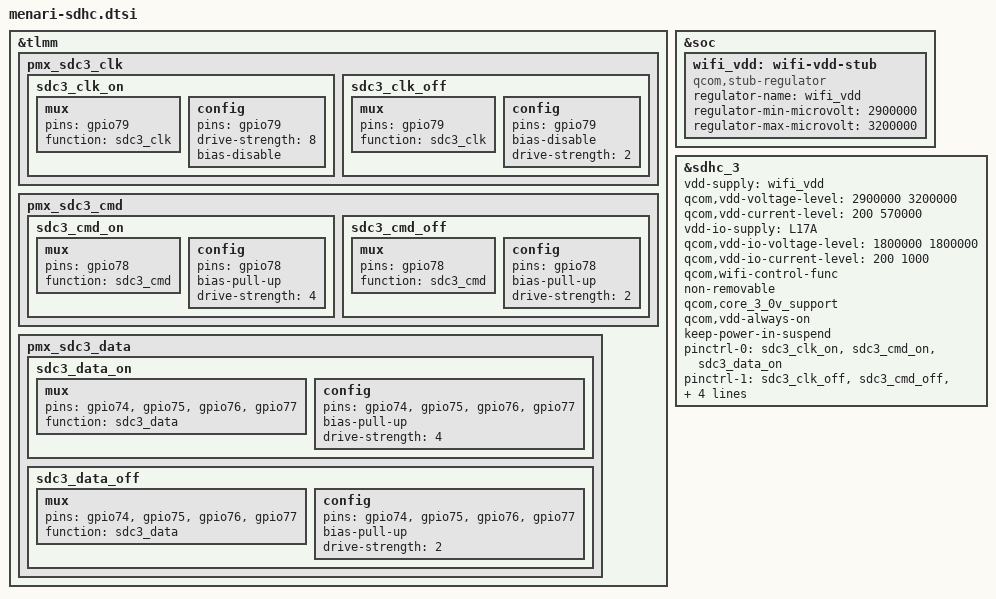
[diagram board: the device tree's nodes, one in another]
// SPDX-License-Identifier: GPL-2.0-only
// Google Agumon wlan SDIO device tree source

&tlmm {
	/* SDC3 Pin Ctrl */
	pmx_sdc3_clk {
		sdc3_clk_on: sdc3_clk_on {
			mux {
				pins = "gpio79";
				function = "sdc3_clk";
			};
			config {
				pins = "gpio79";
				drive-strength = <8>; /* 8 MA */
				bias-disable; /* NO pull */
			};
		};
		sdc3_clk_off: sdc3_clk_off {
			mux {
				pins = "gpio79";
				function = "sdc3_clk";
			};
			config {
				pins = "gpio79";
				bias-disable; /* NO pull */
				drive-strength = <2>; /* 2 MA */
			};
		};
	};
	pmx_sdc3_cmd {
		sdc3_cmd_on: sdc3_cmd_on {
			mux {
				pins = "gpio78";
				function = "sdc3_cmd";
			};
			config {
				pins = "gpio78";
				bias-pull-up; /* pull up */
				drive-strength = <4>; /* 4 MA */
			};
		};
		sdc3_cmd_off: sdc3_cmd_off {
			mux {
				pins = "gpio78";
				function = "sdc3_cmd";
			};
			config {
				pins = "gpio78";
				bias-pull-up; /* pull up */
				drive-strength = <2>; /* 2 MA */
			};
		};
	};
	pmx_sdc3_data {
		sdc3_data_on: sdc3_data_on {
			mux {
				pins = "gpio74","gpio75","gpio76","gpio77";
				function = "sdc3_data";
			};
			config {
				pins = "gpio74","gpio75","gpio76","gpio77";
				bias-pull-up; /* pull up */
				drive-strength = <4>; /* 4 MA */
				};
		};
		sdc3_data_off: sdc3_data_off {
			mux {
				pins = "gpio74","gpio75","gpio76","gpio77";
				function = "sdc3_data";
			};
			config {
				pins = "gpio74","gpio75","gpio76","gpio77";
				bias-pull-up; /* pull up */
				drive-strength = <2>; /* 2 MA */
			};
		};
	};
};

&soc {
	wifi_vdd: wifi-vdd-stub {
		compatible = "qcom,stub-regulator";
		regulator-name = "wifi_vdd";
		regulator-min-microvolt = <2900000>;
		regulator-max-microvolt = <3200000>;
	};
};

&sdhc_3 {
	/* device core power supply for sd card*/
	vdd-supply = <&wifi_vdd>;
	qcom,vdd-voltage-level = <2900000 3200000>;
	qcom,vdd-current-level = <200 570000>;

	/* device communication power supply for msm_io*/
	vdd-io-supply = <&L17A>;
	qcom,vdd-io-voltage-level = <1800000 1800000>;
	qcom,vdd-io-current-level = <200 1000>;
	qcom,wifi-control-func;
	non-removable;
	qcom,core_3_0v_support;
	qcom,vdd-always-on;
	keep-power-in-suspend;
	pinctrl-names = "default", "sleep";
	pinctrl-0 = <&sdc3_clk_on &sdc3_cmd_on &sdc3_data_on>;
	pinctrl-1 = <&sdc3_clk_off &sdc3_cmd_off &sdc3_data_off>;
	qcom,devfreq,freq-table = <400000 20000000 25000000 50000000 100000000 208000000>;
	max-frequency = <208000000>;
	//qcom,bus-speed-mode = "SDR12", "SDR25", "SDR50", "DDR50", "SDR104";
	status = "ok";
};
